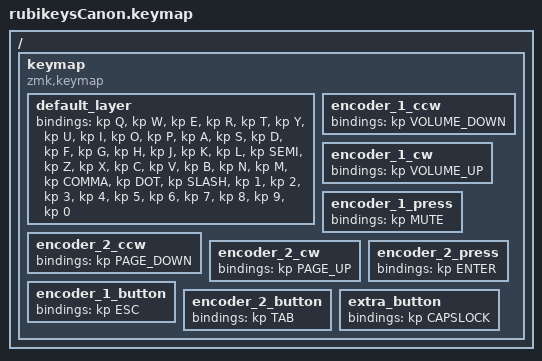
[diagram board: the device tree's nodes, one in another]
#include <behaviors.dtsi>
#include <dt-bindings/zmk/keys.h>

/ {
    keymap {
        compatible = "zmk,keymap";

        default_layer {
            bindings = <
                &kp Q &kp W &kp E &kp R &kp T &kp Y &kp U &kp I &kp O &kp P
                &kp A &kp S &kp D &kp F &kp G &kp H &kp J &kp K &kp L &kp SEMI
                &kp Z &kp X &kp C &kp V &kp B &kp N &kp M &kp COMMA &kp DOT &kp SLASH
                &kp 1 &kp 2 &kp 3 &kp 4 &kp 5 &kp 6 &kp 7 &kp 8 &kp 9 &kp 0
            >;
        };

        encoder_1_ccw {
            bindings = <&kp VOLUME_DOWN>;
        };
        encoder_1_cw {
            bindings = <&kp VOLUME_UP>;
        };
        encoder_1_press {
            bindings = <&kp MUTE>;
        };

        encoder_2_ccw {
            bindings = <&kp PAGE_DOWN>;
        };
        encoder_2_cw {
            bindings = <&kp PAGE_UP>;
        };
        encoder_2_press {
            bindings = <&kp ENTER>;
        };

        encoder_1_button {
            bindings = <&kp ESC>;
        };
        encoder_2_button {
            bindings = <&kp TAB>;
        };

        extra_button {
            bindings = <&kp CAPSLOCK>;
        };
    };
};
